# R7FA6M1AD register map
Vendor: Renesas; Series: RA6; File version: 1.2
CPU: CM4 r0p1, little endian, MPU, FPU, VTOR, 4 interrupt priority bits
Registers are 8-bit, read-write, reset 0x0 unless marked. A register's access mark holds for its fields unless they carry their own. Offsets are from the block's base; [hi:lo] are bit positions; {n}, {i} and the like mark numbered series.

## ICU — Interrupt Controller
Base 0x40006000
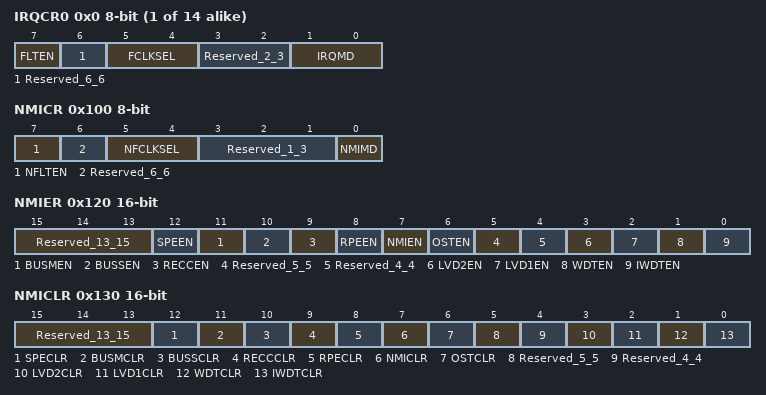
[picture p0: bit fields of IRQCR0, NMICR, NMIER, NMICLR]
{0x0+i} IRQCR{i} (i=0..13) — IRQ Control Register {i}
  [7] FLTEN — IRQ Digital Filter Enable
  [6] Reserved_6_6 — This bit is read as 0. The write value should be 0.
  [5:4] FCLKSEL — IRQ Digital Filter Sampling Clock
  [3:2] Reserved_2_3 — These bits are read as 00. The write value should be 00.
  [1:0] IRQMD — IRQ Detection Sense Select
0x100 NMICR — NMI Pin Interrupt Control Register
  [7] NFLTEN — NMI Digital Filter Enable
  [6] Reserved_6_6 — This bit is read as 0. The write value should be 0.
  [5:4] NFCLKSEL — NMI Digital Filter Sampling Clock
  [3:1] Reserved_1_3 — These bits are read as 000. The write value should be 000.
  [0] NMIMD — NMI Detection Set
0x120 NMIER 16-bit — Non,Maskable Interrupt Enable Register
  [15:13] Reserved_13_15 — These bits are read as 000. The write value should be 000.
  [12] SPEEN — MPU Stack Error Interrupt Enable
  [11] BUSMEN — MPU Bus Master Error Interrupt Enable
  [10] BUSSEN — MPU Bus Slave Error Interrupt Enable
  [9] RECCEN — RAM ECC Error Interrupt Enable
  [8] RPEEN — RAM Parity Error Interrupt Enable
  [7] NMIEN — NMI Pin Interrupt Enable
  [6] OSTEN — Oscillation Stop Detection Interrupt Enable
  [5] Reserved_5_5 — This bit is read as 0. The write value should be 0.
  [4] Reserved_4_4 — This bit is read as 0. The write value should be 0.
  [3] LVD2EN — Voltage,Monitoring 2 Interrupt Enable
  [2] LVD1EN — Voltage,Monitoring 1 Interrupt Enable
  [1] WDTEN — WDT Underflow/Refresh Error Interrupt Enable
  [0] IWDTEN — IWDT Underflow/Refresh Error Interrupt Enable
0x130 NMICLR 16-bit wo — Non,Maskable Interrupt Status Clear Register
  [15:13] Reserved_13_15 — The write value should be 000.
  [12] SPECLR — SPEST Clear
  [11] BUSMCLR — BUSMST Clear
  [10] BUSSCLR — BUSSST Clear
  [9] RECCCLR — RECCST Clear
  [8] RPECLR — RPEST Clear
  [7] NMICLR — NMIST Clear
  [6] OSTCLR — OSTST Clear
  [5] Reserved_5_5 — The write value should be 0.
  [4] Reserved_4_4 — The write value should be 0.
  [3] LVD2CLR — LVD2ST Clear
  [2] LVD1CLR — LVD1ST Clear
  [1] WDTCLR — WDTST Clear
  [0] IWDTCLR — IWDTST Clear
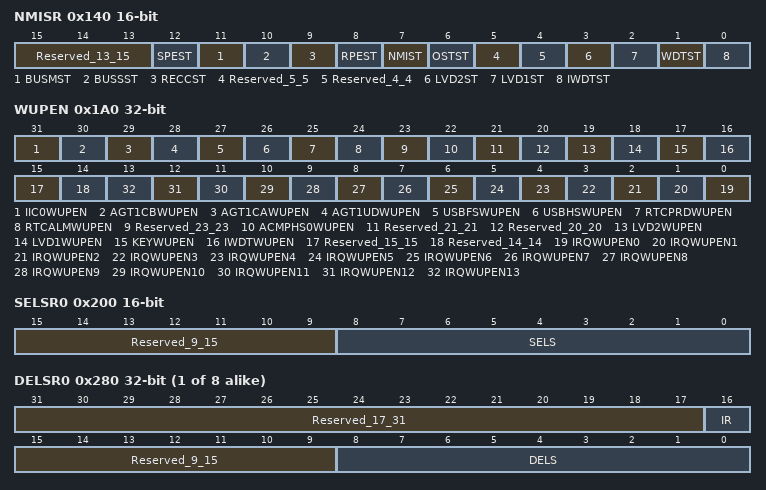
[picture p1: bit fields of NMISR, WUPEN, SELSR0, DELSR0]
0x140 NMISR 16-bit ro — Non,Maskable Interrupt Status Register
  [15:13] Reserved_13_15 — These bits are read as 000.
  [12] SPEST — MPU Stack Error Interrupt Status Flag
  [11] BUSMST — MPU Bus Master Error Interrupt Status Flag
  [10] BUSSST — MPU Bus Slave Error Interrupt Status Flag
  [9] RECCST — RAM ECC Error Interrupt Status Flag
  [8] RPEST — RAM Parity Error Interrupt Status Flag
  [7] NMIST — NMI Status Flag
  [6] OSTST — Oscillation Stop Detection Interrupt Status Flag
  [5] Reserved_5_5 — This bit is read as 0.
  [4] Reserved_4_4 — This bit is read as 0.
  [3] LVD2ST — Voltage,Monitoring 2 Interrupt Status Flag
  [2] LVD1ST — Voltage,Monitoring 1 Interrupt Status Flag
  [1] WDTST — WDT Underflow/Refresh Error Status Flag
  [0] IWDTST — IWDT Underflow/Refresh Error Status Flag
0x1A0 WUPEN 32-bit — Wake Up interrupt enable register
  [31] IIC0WUPEN — IIC0 address match interrupt S/W standby returns enable bit
  [30] AGT1CBWUPEN — AGT1 compare match B interrupt S/W standby returns enable bit
  [29] AGT1CAWUPEN — AGT1 compare match A interrupt S/W standby returns enable bit
  [28] AGT1UDWUPEN — AGT1 underflow interrupt S/W standby returns enable bit
  [27] USBFSWUPEN — USBFS interrupt S/W standby returns enable bit
  [26] USBHSWUPEN — USBHS interrupt S/W standby returns enable bit
  [25] RTCPRDWUPEN — RCT period interrupt S/W standby returns enable bit
  [24] RTCALMWUPEN — RTC alarm interrupt S/W standby returns enable bit
  [23] Reserved_23_23 — This bit is read as 0. The write value should be 0.
  [22] ACMPHS0WUPEN — ACMPHS0 interrupt S/W standby returns enable bit
  [21] Reserved_21_21 — This bit is read as 0. The write value should be 0.
  [20] Reserved_20_20 — This bit is read as 0. The write value should be 0.
  [19] LVD2WUPEN — LVD2 interrupt S/W standby returns enable bit
  [18] LVD1WUPEN — LVD1 interrupt S/W standby returns enable bit
  [17] KEYWUPEN — Key interrupt S/W standby returns enable bit
  [16] IWDTWUPEN — IWDT interrupt S/W standby returns enable bit
  [15] Reserved_15_15 — This bit is read as 0. The write value should be 0.
  [14] Reserved_14_14 — This bit is read as 0. The write value should be 0.
  [n] IRQWUPEN{n} (n=0..13) — IRQ{n} interrupt S/W standby returns enable bit
0x200 SELSR0 16-bit — SYS Event Link Setting Register
  [15:9] Reserved_9_15 — These bits are read as 0000000. The write value should be 0000000.
  [8:0] SELS — SYS Event Link Select
{0x280+4i} DELSR{i} (i=0..7) 32-bit (reset mask 0xFFFF) — DMAC Event Link Setting Register {i}
  [31:17] Reserved_17_31 — These bits are read as 000000000000000. The write value should be 000000000000000.
  [16] IR — Interrupt Status Flag for DMAC
  [15:9] Reserved_9_15 — These bits are read as 0000000. The write value should be 0000000.
  [8:0] DELS — DMAC Event Link Select
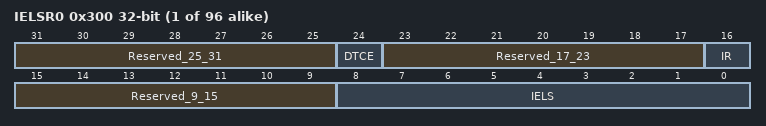
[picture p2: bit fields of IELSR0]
{0x300+4i} IELSR{i} (i=0..95) 32-bit — INT Event Link Setting Register {i}
  [31:25] Reserved_25_31 — These bits are read as 0000000. The write value should be 0000000.
  [24] DTCE — DTC Activation Enable
  [23:17] Reserved_17_23 — These bits are read as 0000000. The write value should be 0000000.
  [16] IR — Interrupt Status Flag
  [15:9] Reserved_9_15 — These bits are read as 0000000. The write value should be 0000000.
  [8:0] IELS — Event selection to NVIC
